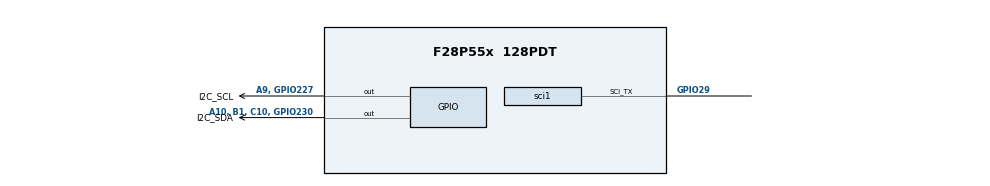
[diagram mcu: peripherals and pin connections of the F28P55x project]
/**
 * @cliArgs --device "F28P55x" --part "F28P55x_128PDT" --package "128PDT" --context "system" --product "C2000WARE@5.05.00.00"
 * @versions {"tool":"1.24.0+4110"}
 */

/**
 * Import the modules used in this configuration.
 */
const gpio  = scripting.addModule("/driverlib/gpio.js", {}, false);
const gpio1 = gpio.addInstance();
const gpio2 = gpio.addInstance();
const sci   = scripting.addModule("/driverlib/sci.js", {}, false);
const sci1  = sci.addInstance();

/**
 * Write custom configuration values to the imported modules.
 */
gpio1.$name             = "I2C_SDA";
gpio1.direction         = "GPIO_DIR_MODE_OUT";
gpio1.padConfig         = "OD_PULLUP";
gpio1.writeInitialValue = true;
gpio1.initialValue      = 1;
gpio1.gpioPin.$assign   = "A10, B1, C10, GPIO230";

gpio2.$name             = "I2C_SCL";
gpio2.padConfig         = "OD_PULLUP";
gpio2.writeInitialValue = true;
gpio2.initialValue      = 1;
gpio2.direction         = "GPIO_DIR_MODE_OUT";
gpio2.gpioPin.$assign   = "A9, GPIO227";

sci1.$name                 = "mySCI0";
sci1.useInterrupts         = false;
sci1.useFifo               = false;
sci1.sci.sci_txPin.$assign = "GPIO29";
sci1.rxQual.$name          = "myGPIOQUAL0";
sci1.txQual.$name          = "myGPIOQUAL1";

/**
 * Pinmux solution for unlocked pins/peripherals. This ensures that minor changes to the automatic solver in a future
 * version of the tool will not impact the pinmux you originally saw.  These lines can be completely deleted in order to
 * re-solve from scratch.
 */
sci1.sci.$suggestSolution           = "SCIA";
sci1.sci.sci_rxPin.$suggestSolution = "A16, B16, C16, GPIO28";
